VERSION ""

NS_ :

BS_:

BU_: DBW AKit Pacifica MPDM_Master MPDM_Requester

BO_ 3221225472 VECTOR__INDEPENDENT_SIG_MSG: 0 Vector__XXX
 SG_ DBW_SteeringWhlCurvDes m1 : 0|14@1- (0.0001,0) [-0.8192|0.8191] "1/m" Vector__XXX
 SG_ DBW_SteeringWhlCurvAct m1 : 0|14@1- (0.0001,0) [-0.8192|0.8191] "1/m" Vector__XXX
 SG_ DBW_SteeringUnitType M : 52|1@1+ (1,0) [0|1] "" Vector__XXX
 SG_ DBW_MiscFault_AccelRpt : 52|1@1+ (1,0) [0|1] "Bool" Vector__XXX
 SG_ DBW_MiscFault_BrkRpt : 49|1@1+ (1,0) [0|1] "Bool" Vector__XXX
 SG_ DBW_MiscFault_SteerRpt : 51|1@1+ (1,0) [0|1] "Bool" Vector__XXX
 SG_ AKit_SteeringWhlQuiet : 51|1@1+ (1,0) [0|1] "" Vector__XXX
 SG_ NewSignal_0004 : 0|8@1+ (1,0) [0|0] "" Vector__XXX
 SG_ NewSignal_0001 : 0|8@1+ (1,0) [0|0] "" Vector__XXX
 SG_ NewSignal_0008 : 32|8@1+ (1,0) [0|0] "" Vector__XXX
 SG_ NewSignal_0006 : 0|8@1+ (1,0) [0|0] "" Vector__XXX
 SG_ NewSignal_0002 : 0|8@1+ (1,0) [0|0] "" Vector__XXX
 SG_ NewSignal_0003 : 0|8@1+ (1,0) [0|0] "" Vector__XXX
 SG_ DBW_Mdpm2Fuse01 : 0|2@1+ (1,0) [0|3] "enum" Vector__XXX
 SG_ DBW_Mdpm2Fuse02 : 2|2@1+ (1,0) [0|3] "enum" Vector__XXX
 SG_ DBW_Mdpm2Fuse03 : 4|2@1+ (1,0) [0|3] "enum" Vector__XXX
 SG_ DBW_Mdpm2Fuse04 : 6|2@1+ (1,0) [0|3] "enum" Vector__XXX
 SG_ DBW_Mdpm2Fuse05 : 8|2@1+ (1,0) [0|3] "enum" Vector__XXX
 SG_ DBW_Mdpm2Fuse06 : 10|2@1+ (1,0) [0|3] "enum" Vector__XXX
 SG_ DBW_Mdpm2Fuse07 : 12|2@1+ (1,0) [0|3] "enum" Vector__XXX
 SG_ DBW_Mdpm2Fuse08 : 14|2@1+ (1,0) [0|3] "enum" Vector__XXX
 SG_ DBW_Mdpm2Fuse09 : 16|2@1+ (1,0) [0|3] "enum" Vector__XXX
 SG_ DBW_Mdpm2Fuse10 : 18|2@1+ (1,0) [0|3] "enum" Vector__XXX
 SG_ DBW_Mdpm2Fuse11 : 20|2@1+ (1,0) [0|3] "enum" Vector__XXX
 SG_ DBW_Mdpm2Fuse12 : 22|2@1+ (1,0) [0|3] "enum" Vector__XXX
 SG_ DBW_Mdpm2Fuse13 : 24|2@1+ (1,0) [0|3] "enum" Vector__XXX
 SG_ DBW_Mdpm2Fuse14 : 26|2@1+ (1,0) [0|3] "enum" Vector__XXX
 SG_ DBW_Mdpm2Fuse15 : 28|2@1+ (1,0) [0|3] "enum" Vector__XXX
 SG_ DBW_Mdpm2Fuse16 : 30|2@1+ (1,0) [0|3] "enum" Vector__XXX
 SG_ DBW_Mdpm2Relay01 : 32|4@1+ (1,0) [0|15] "enum" Vector__XXX
 SG_ DBW_Mdpm2Relay02 : 36|4@1+ (1,0) [0|15] "enum" Vector__XXX
 SG_ DBW_Mdpm2Relay03 : 40|4@1+ (1,0) [0|15] "enum" Vector__XXX
 SG_ DBW_Mdpm2Relay04 : 44|4@1+ (1,0) [0|15] "enum" Vector__XXX
 SG_ DBW_Mdpm2Relay05 : 48|4@1+ (1,0) [0|15] "enum" Vector__XXX
 SG_ DBW_Mdpm2Relay06 : 52|4@1+ (1,0) [0|15] "enum" Vector__XXX
 SG_ DBW_Mdpm2Relay07 : 56|4@1+ (1,0) [0|15] "enum" Vector__XXX
 SG_ DBW_Mdpm2Relay08 : 60|4@1+ (1,0) [0|15] "enum" Vector__XXX
 SG_ AKit_Mdpm1Relay01Cmd : 0|2@1+ (1,0) [0|3] "enum" Vector__XXX
 SG_ AKit_Mdpm1Relay02Cmd : 2|2@1+ (1,0) [0|3] "enum" Vector__XXX
 SG_ AKit_Mdpm1Relay03Cmd : 4|2@1+ (1,0) [0|3] "enum" Vector__XXX
 SG_ AKit_Mdpm1Relay04Cmd : 6|2@1+ (1,0) [0|3] "enum" Vector__XXX
 SG_ AKit_Mdpm1Relay05Cmd : 8|2@1+ (1,0) [0|3] "enum" Vector__XXX
 SG_ AKit_Mdpm1Relay06Cmd : 10|2@1+ (1,0) [0|3] "enum" Vector__XXX
 SG_ AKit_Mdpm1Relay07Cmd : 12|2@1+ (1,0) [0|3] "enum" Vector__XXX
 SG_ AKit_Mdpm1Relay08Cmd : 14|2@1+ (1,0) [0|3] "enum" Vector__XXX
 SG_ AKit_Mdpm2Relay01Cmd : 16|2@1+ (1,0) [0|3] "enum" Vector__XXX
 SG_ AKit_Mdpm2Relay02Cmd : 18|2@1+ (1,0) [0|3] "enum" Vector__XXX
 SG_ AKit_Mdpm2Relay03Cmd : 20|2@1+ (1,0) [0|3] "enum" Vector__XXX
 SG_ AKit_Mdpm2Relay04Cmd : 22|2@1+ (1,0) [0|3] "enum" Vector__XXX
 SG_ AKit_Mdpm2Relay05Cmd : 24|2@1+ (1,0) [0|3] "enum" Vector__XXX
 SG_ AKit_Mdpm2Relay06Cmd : 26|2@1+ (1,0) [0|3] "enum" Vector__XXX
 SG_ AKit_Mdpm2Relay07Cmd : 28|2@1+ (1,0) [0|3] "enum" Vector__XXX
 SG_ AKit_Mdpm2Relay08Cmd : 30|2@1+ (1,0) [0|3] "enum" Vector__XXX
 SG_ AKit_MdpmCmdWatchdogCntr : 56|4@1+ (1,0) [0|3] "" Vector__XXX
 SG_ DBW_Mdpm1Fuse01 : 0|2@1+ (1,0) [0|3] "enum" Vector__XXX
 SG_ DBW_Mdpm1Fuse02 : 2|2@1+ (1,0) [0|3] "enum" Vector__XXX
 SG_ DBW_Mdpm1Fuse03 : 4|2@1+ (1,0) [0|3] "enum" Vector__XXX
 SG_ DBW_Mdpm1Fuse04 : 6|2@1+ (1,0) [0|3] "enum" Vector__XXX
 SG_ DBW_Mdpm1Fuse05 : 8|2@1+ (1,0) [0|3] "enum" Vector__XXX
 SG_ DBW_Mdpm1Fuse06 : 10|2@1+ (1,0) [0|3] "enum" Vector__XXX
 SG_ DBW_Mdpm1Fuse07 : 12|2@1+ (1,0) [0|3] "enum" Vector__XXX
 SG_ DBW_Mdpm1Fuse08 : 14|2@1+ (1,0) [0|3] "enum" Vector__XXX
 SG_ DBW_Mdpm1Fuse09 : 16|2@1+ (1,0) [0|3] "enum" Vector__XXX
 SG_ DBW_Mdpm1Fuse10 : 18|2@1+ (1,0) [0|3] "enum" Vector__XXX
 SG_ DBW_Mdpm1Fuse11 : 20|2@1+ (1,0) [0|3] "enum" Vector__XXX
 SG_ DBW_Mdpm1Fuse12 : 22|2@1+ (1,0) [0|3] "enum" Vector__XXX
 SG_ DBW_Mdpm1Fuse13 : 24|2@1+ (1,0) [0|3] "enum" Vector__XXX
 SG_ DBW_Mdpm1Fuse14 : 26|2@1+ (1,0) [0|3] "enum" Vector__XXX
 SG_ DBW_Mdpm1Fuse15 : 28|2@1+ (1,0) [0|3] "enum" Vector__XXX
 SG_ DBW_Mdpm1Fuse16 : 30|2@1+ (1,0) [0|3] "enum" Vector__XXX
 SG_ DBW_Mdpm1Relay01 : 32|4@1+ (1,0) [0|15] "enum" Vector__XXX
 SG_ DBW_Mdpm1Relay02 : 36|4@1+ (1,0) [0|15] "enum" Vector__XXX
 SG_ DBW_Mdpm1Relay03 : 40|4@1+ (1,0) [0|15] "enum" Vector__XXX
 SG_ DBW_Mdpm1Relay04 : 44|4@1+ (1,0) [0|15] "enum" Vector__XXX
 SG_ DBW_Mdpm1Relay05 : 48|4@1+ (1,0) [0|15] "enum" Vector__XXX
 SG_ DBW_Mdpm1Relay06 : 52|4@1+ (1,0) [0|15] "enum" Vector__XXX
 SG_ DBW_Mdpm1Relay07 : 56|4@1+ (1,0) [0|15] "enum" Vector__XXX
 SG_ DBW_Mdpm1Relay08 : 60|4@1+ (1,0) [0|15] "enum" Vector__XXX
 SG_ DBW_GpsLong : 0|32@1+ (0.301749,0) [-648000000|648000000] "mas" Vector__XXX
 SG_ DBW_GpsLat : 32|32@1+ (0.301749,0) [-324000000|324000000] "mas" Vector__XXX
 SG_ VinMultiplexor M : 0|2@1+ (1,0) [0|2] "" Vector__XXX
 SG_ VinDigit_01 m0 : 8|8@1+ (1,0) [30|90] "ascii" Vector__XXX
 SG_ VinDigit_02 m0 : 16|8@1+ (1,0) [30|90] "ascii" Vector__XXX
 SG_ VinDigit_03 m0 : 24|8@1+ (1,0) [30|90] "ascii" Vector__XXX
 SG_ VinDigit_04 m0 : 32|8@1+ (1,0) [30|90] "ascii" Vector__XXX
 SG_ VinDigit_05 m0 : 40|8@1+ (1,0) [30|90] "ascii" Vector__XXX
 SG_ VinDigit_06 m0 : 48|8@1+ (1,0) [30|90] "ascii" Vector__XXX
 SG_ VinDigit_07 m0 : 56|8@1+ (1,0) [30|90] "ascii" Vector__XXX
 SG_ VinDigit_08 m1 : 8|8@1+ (1,0) [30|90] "ascii" Vector__XXX
 SG_ VinDigit_09 m1 : 16|8@1+ (1,0) [30|90] "ascii" Vector__XXX
 SG_ VinDigit_10 m1 : 24|8@1+ (1,0) [30|90] "ascii" Vector__XXX
 SG_ VinDigit_11 m1 : 32|8@1+ (1,0) [30|90] "ascii" Vector__XXX
 SG_ VinDigit_12 m1 : 40|8@1+ (1,0) [30|90] "ascii" Vector__XXX
 SG_ VinDigit_13 m1 : 48|8@1+ (1,0) [30|90] "ascii" Vector__XXX
 SG_ VinDigit_14 m1 : 56|8@1+ (1,0) [30|90] "ascii" Vector__XXX
 SG_ VinDigit_15 m2 : 8|8@1+ (1,0) [30|90] "ascii" Vector__XXX
 SG_ VinDigit_16 m2 : 16|8@1+ (1,0) [30|90] "ascii" Vector__XXX
 SG_ VinDigit_17 m2 : 24|8@1+ (1,0) [30|90] "ascii" Vector__XXX

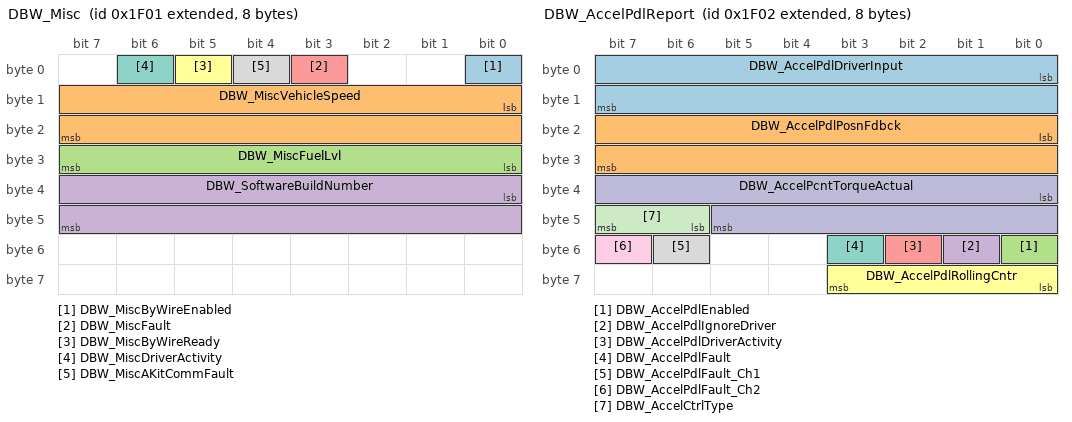
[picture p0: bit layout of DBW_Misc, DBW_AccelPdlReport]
BO_ 2147491585 DBW_Misc: 8 DBW
 SG_ DBW_MiscByWireEnabled : 0|1@1+ (1,0) [0|1] "Bool" Vector__XXX
 SG_ DBW_MiscVehicleSpeed : 8|16@1+ (0.00217014,0) [0|142.22] "m/s" Vector__XXX
 SG_ DBW_MiscFuelLvl : 24|8@1+ (0.5,0) [0|100] "%" Vector__XXX
 SG_ DBW_SoftwareBuildNumber : 32|16@1+ (1,0) [0|65535] "" Vector__XXX
 SG_ DBW_MiscFault : 3|1@1+ (1,0) [0|1] "Bool" Vector__XXX
 SG_ DBW_MiscByWireReady : 5|1@1+ (1,0) [0|1] "Bool" Vector__XXX
 SG_ DBW_MiscDriverActivity : 6|1@1+ (1,0) [0|1] "Bool" Vector__XXX
 SG_ DBW_MiscAKitCommFault : 4|1@1+ (1,0) [0|1] "Bool" Vector__XXX

BO_ 2147491586 DBW_AccelPdlReport: 8 DBW
 SG_ DBW_AccelPdlDriverInput : 0|16@1+ (0.1,0) [0|100] "%-pedal" Vector__XXX
 SG_ DBW_AccelPdlPosnFdbck : 16|16@1+ (0.1,0) [0|100] "%-pedal" Vector__XXX
 SG_ DBW_AccelPdlEnabled : 48|1@1+ (1,0) [0|1] "Bool" Vector__XXX
 SG_ DBW_AccelPdlIgnoreDriver : 49|1@1+ (1,0) [0|1] "Bool" Vector__XXX
 SG_ DBW_AccelPdlDriverActivity : 50|1@1+ (1,0) [0|1] "Bool" Vector__XXX
 SG_ DBW_AccelPdlRollingCntr : 56|4@1+ (1,0) [0|15] "" Vector__XXX
 SG_ DBW_AccelPdlFault : 51|1@1+ (1,0) [0|1] "Bool" Vector__XXX
 SG_ DBW_AccelPdlFault_Ch1 : 54|1@1+ (1,0) [0|1] "Bool" Vector__XXX
 SG_ DBW_AccelPdlFault_Ch2 : 55|1@1+ (1,0) [0|1] "Bool" Vector__XXX
 SG_ DBW_AccelPcntTorqueActual : 32|14@1+ (0.1,0) [0|100] "%-pedal" Vector__XXX
 SG_ DBW_AccelCtrlType : 46|2@1+ (1,0) [0|3] "Enum" Vector__XXX

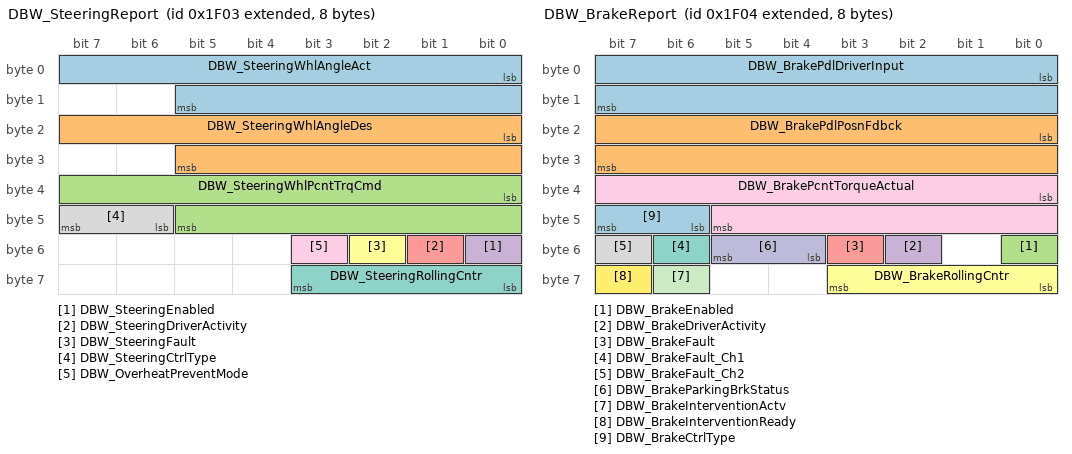
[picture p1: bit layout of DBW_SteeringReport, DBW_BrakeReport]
BO_ 2147491587 DBW_SteeringReport: 8 DBW
 SG_ DBW_SteeringWhlAngleAct : 0|14@1- (0.1,0) [-600|600] "deg" Vector__XXX
 SG_ DBW_SteeringWhlAngleDes : 16|14@1- (0.1,0) [-600|600] "deg" Vector__XXX
 SG_ DBW_SteeringWhlPcntTrqCmd : 32|14@1- (0.02,0) [-100|100] "%-torque" Vector__XXX
 SG_ DBW_SteeringEnabled : 48|1@1+ (1,0) [0|1] "Bool" Vector__XXX
 SG_ DBW_SteeringDriverActivity : 49|1@1+ (1,0) [0|1] "Bool" Vector__XXX
 SG_ DBW_SteeringFault : 50|1@1+ (1,0) [0|1] "Bool" Vector__XXX
 SG_ DBW_SteeringRollingCntr : 56|4@1+ (1,0) [0|15] "" Vector__XXX
 SG_ DBW_SteeringCtrlType : 46|2@1+ (1,0) [0|3] "Enum" Vector__XXX
 SG_ DBW_OverheatPreventMode : 51|1@1+ (1,0) [0|1] "Bool" Vector__XXX

BO_ 2147491588 DBW_BrakeReport: 8 DBW
 SG_ DBW_BrakePdlDriverInput : 0|16@1+ (0.1,0) [0|100] "%-pedal" Vector__XXX
 SG_ DBW_BrakePdlPosnFdbck : 16|16@1+ (0.1,0) [0|100] "%-pedal" Vector__XXX
 SG_ DBW_BrakeEnabled : 48|1@1+ (1,0) [0|1] "Bool" Vector__XXX
 SG_ DBW_BrakeDriverActivity : 50|1@1+ (1,0) [0|1] "Bool" Vector__XXX
 SG_ DBW_BrakeFault : 51|1@1+ (1,0) [0|1] "Bool" Vector__XXX
 SG_ DBW_BrakeRollingCntr : 56|4@1+ (1,0) [0|15] "" Vector__XXX
 SG_ DBW_BrakeFault_Ch1 : 54|1@1+ (1,0) [0|1] "Bool" Vector__XXX
 SG_ DBW_BrakeFault_Ch2 : 55|1@1+ (1,0) [0|1] "Bool" Vector__XXX
 SG_ DBW_BrakePcntTorqueActual : 32|14@1+ (0.1,0) [0|100] "%-torque" Vector__XXX
 SG_ DBW_BrakeParkingBrkStatus : 52|2@1+ (1,0) [0|3] "Enum" Vector__XXX
 SG_ DBW_BrakeInterventionActv : 62|1@1+ (1,0) [0|1] "Bool" Vector__XXX
 SG_ DBW_BrakeInterventionReady : 63|1@1+ (1,0) [0|1] "Bool" Vector__XXX
 SG_ DBW_BrakeCtrlType : 46|2@1+ (1,0) [0|3] "Enum" Vector__XXX

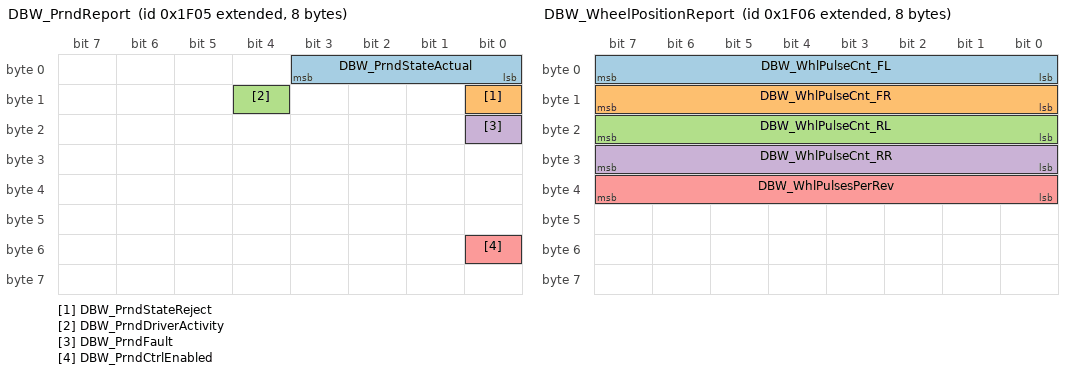
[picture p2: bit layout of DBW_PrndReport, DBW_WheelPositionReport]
BO_ 2147491589 DBW_PrndReport: 8 DBW
 SG_ DBW_PrndStateActual : 0|4@1+ (1,0) [0|4] "Enum" Vector__XXX
 SG_ DBW_PrndStateReject : 8|1@1+ (1,0) [0|1] "Bool" Vector__XXX
 SG_ DBW_PrndDriverActivity : 12|1@1+ (1,0) [0|1] "Bool" Vector__XXX
 SG_ DBW_PrndFault : 16|1@1+ (1,0) [0|1] "Bool" Vector__XXX
 SG_ DBW_PrndCtrlEnabled : 48|1@1+ (1,0) [0|1] "Bool" Vector__XXX

BO_ 2147491590 DBW_WheelPositionReport: 8 DBW
 SG_ DBW_WhlPulseCnt_FL : 0|8@1+ (1,0) [0|254] "Count" Vector__XXX
 SG_ DBW_WhlPulseCnt_FR : 8|8@1+ (1,0) [0|254] "Count" Vector__XXX
 SG_ DBW_WhlPulseCnt_RL : 16|8@1+ (1,0) [0|254] "Count" Vector__XXX
 SG_ DBW_WhlPulseCnt_RR : 24|8@1+ (1,0) [0|254] "Count" Vector__XXX
 SG_ DBW_WhlPulsesPerRev : 32|8@1+ (1,0) [0|255] "Count" Vector__XXX

BO_ 2147495682 AKit_AccelPdlRequest: 8 AKit
 SG_ AKit_AccelPdlReq m0 : 0|14@1+ (0.1,0) [0|100] "%-pedal" Vector__XXX
 SG_ AKit_AccelPdlEnblReq : 48|1@1+ (1,0) [0|1] "Bool" Vector__XXX
 SG_ Akit_AccelPdlIgnoreDriverOvrd : 50|1@1+ (1,0) [0|1] "Bool" Vector__XXX
 SG_ AKit_AccelPdlRollingCntr : 56|4@1+ (1,0) [0|15] "" Vector__XXX
 SG_ AKit_AccelReqType M : 54|2@1+ (1,0) [0|3] "Enum" Vector__XXX
 SG_ AKit_AccelPcntTorqueReq m1 : 0|14@1+ (0.1,0) [0|100] "%-torque" Vector__XXX
 SG_ AKit_SpeedReq m2 : 0|14@1+ (0.005,0) [0|81.915] "m/s" Vector__XXX
 SG_ AKit_SpeedModeRoadSlope m2 : 32|8@1- (0.2,0) [-25.5|25.5] "degrees" Vector__XXX

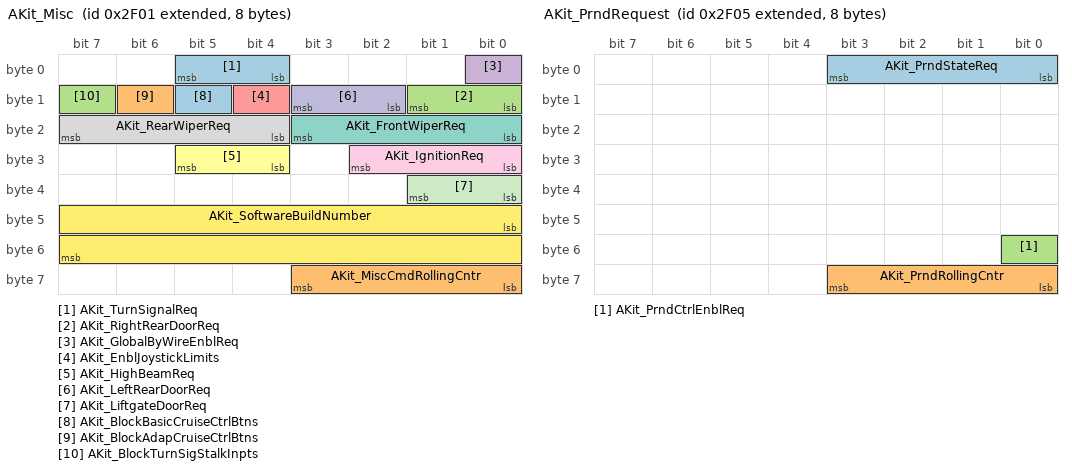
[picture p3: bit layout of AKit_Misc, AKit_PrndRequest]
BO_ 2147495681 AKit_Misc: 8 AKit
 SG_ AKit_TurnSignalReq : 4|2@1+ (1,0) [0|3] "Enum" Vector__XXX
 SG_ AKit_MiscCmdRollingCntr : 56|4@1+ (1,0) [0|15] "" Vector__XXX
 SG_ AKit_RightRearDoorReq : 8|2@1+ (1,0) [0|3] "Enum" Vector__XXX
 SG_ AKit_GlobalByWireEnblReq : 0|1@1+ (1,0) [0|1] "Bool" Vector__XXX
 SG_ AKit_EnblJoystickLimits : 12|1@1+ (1,0) [0|1] "Bool" Vector__XXX
 SG_ AKit_HighBeamReq : 28|2@1+ (1,0) [0|0] "" Vector__XXX
 SG_ AKit_FrontWiperReq : 16|4@1+ (1,0) [0|15] "Enum" Vector__XXX
 SG_ AKit_RearWiperReq : 20|4@1+ (1,0) [0|15] "Enum" Vector__XXX
 SG_ AKit_IgnitionReq : 24|3@1+ (1,0) [0|7] "Enum" Vector__XXX
 SG_ AKit_LeftRearDoorReq : 10|2@1+ (1,0) [0|3] "Enum" Vector__XXX
 SG_ AKit_LiftgateDoorReq : 32|2@1+ (1,0) [0|3] "Enum" Vector__XXX
 SG_ AKit_SoftwareBuildNumber : 40|16@1+ (1,0) [0|65535] "" Vector__XXX
 SG_ AKit_BlockBasicCruiseCtrlBtns : 13|1@1+ (1,0) [0|1] "" Vector__XXX
 SG_ AKit_BlockAdapCruiseCtrlBtns : 14|1@1+ (1,0) [0|1] "" Vector__XXX
 SG_ AKit_BlockTurnSigStalkInpts : 15|1@1+ (1,0) [0|1] "" Vector__XXX

BO_ 2147495683 AKit_SteeringRequest: 8 AKit
 SG_ AKit_SteeringWhlAngleReq m1 : 0|14@1- (0.1,0) [-500|500] "deg" Vector__XXX
 SG_ AKit_SteeringWhlAngleVelocityLim : 16|16@1- (1,0) [0|498] "deg/s" Vector__XXX
 SG_ AKit_SteerCtrlEnblReq : 48|1@1+ (1,0) [0|0] "" Vector__XXX
 SG_ AKit_SteerRollingCntr : 56|4@1+ (1,0) [0|15] "" Vector__XXX
 SG_ AKit_SteeringWhlIgnoreDriverOvrd : 50|1@1+ (1,0) [0|1] "" Vector__XXX
 SG_ AKit_SteeringWhlPcntTrqReq m0 : 0|14@1- (0.02,0) [-100|100] "%-torque" Vector__XXX
 SG_ AKit_SteeringReqType M : 54|2@1+ (1,0) [0|3] "Enum" Vector__XXX
 SG_ AKit_SteeringVehCurvatureReq m2 : 0|14@1- (0.0001,0) [-0.8192|0.8191] "1/m" Vector__XXX

BO_ 2147495684 AKit_BrakeRequest: 8 AKit
 SG_ AKit_BrakePedalReq m0 : 0|14@1+ (0.1,0) [0|100] "%-pedal" Vector__XXX
 SG_ AKit_BrakeRollingCntr : 56|4@1+ (1,0) [0|15] "" Vector__XXX
 SG_ AKit_BrakeCtrlEnblReq : 48|1@1+ (1,0) [0|1] "Bool" Vector__XXX
 SG_ AKit_BrakeCtrlReqType M : 54|2@1+ (1,0) [0|3] "Enum" Vector__XXX
 SG_ AKit_BrakePcntTorqueReq m1 : 0|14@1+ (0.1,0) [0|100] "%-torque" Vector__XXX
 SG_ AKit_SpeedModeAccelLim m2 : 16|8@1+ (0.1,0) [0|25.5] "m/s^2" Vector__XXX
 SG_ AKit_SpeedModeDecelLim m2 : 24|8@1+ (0.1,0) [0|25.5] "m/s^2" Vector__XXX

BO_ 2147495685 AKit_PrndRequest: 8 AKit
 SG_ AKit_PrndStateReq : 0|4@1+ (1,0) [0|5] "Enum" Vector__XXX
 SG_ AKit_PrndRollingCntr : 56|4@1+ (1,0) [0|15] "" Vector__XXX
 SG_ AKit_PrndCtrlEnblReq : 48|1@1+ (1,0) [0|1] "Bool" Vector__XXX

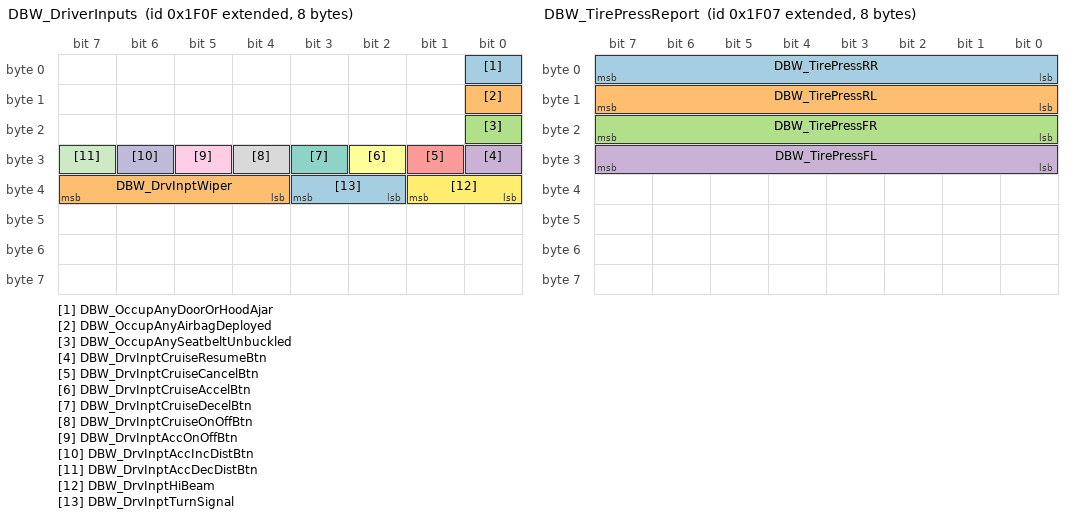
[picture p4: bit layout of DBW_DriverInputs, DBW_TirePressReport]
BO_ 2147491599 DBW_DriverInputs: 8 AKit
 SG_ DBW_OccupAnyDoorOrHoodAjar : 0|1@1+ (1,0) [0|1] "Bool" Vector__XXX
 SG_ DBW_OccupAnyAirbagDeployed : 8|1@1+ (1,0) [0|1] "Bool" Vector__XXX
 SG_ DBW_OccupAnySeatbeltUnbuckled : 16|1@1+ (1,0) [0|1] "Bool" Vector__XXX
 SG_ DBW_DrvInptCruiseResumeBtn : 24|1@1+ (1,0) [0|1] "Bool" Vector__XXX
 SG_ DBW_DrvInptCruiseCancelBtn : 25|1@1+ (1,0) [0|1] "Bool" Vector__XXX
 SG_ DBW_DrvInptCruiseAccelBtn : 26|1@1+ (1,0) [0|1] "Bool" Vector__XXX
 SG_ DBW_DrvInptCruiseDecelBtn : 27|1@1+ (1,0) [0|1] "Bool" Vector__XXX
 SG_ DBW_DrvInptCruiseOnOffBtn : 28|1@1+ (1,0) [0|1] "Bool" Vector__XXX
 SG_ DBW_DrvInptAccOnOffBtn : 29|1@1+ (1,0) [0|1] "Bool" Vector__XXX
 SG_ DBW_DrvInptAccIncDistBtn : 30|1@1+ (1,0) [0|1] "Bool" Vector__XXX
 SG_ DBW_DrvInptAccDecDistBtn : 31|1@1+ (1,0) [0|1] "Bool" Vector__XXX
 SG_ DBW_DrvInptHiBeam : 32|2@1+ (1,0) [0|3] "enum" Vector__XXX
 SG_ DBW_DrvInptTurnSignal : 34|2@1+ (1,0) [0|3] "enum" Vector__XXX
 SG_ DBW_DrvInptWiper : 36|4@1+ (1,0) [0|15] "enum" Vector__XXX

BO_ 2147491591 DBW_TirePressReport: 8 DBW
 SG_ DBW_TirePressRR : 0|8@1+ (6.89476,0) [0|868.739] "kPa" Vector__XXX
 SG_ DBW_TirePressRL : 8|8@1+ (6.89476,0) [0|868.739] "kPa" Vector__XXX
 SG_ DBW_TirePressFR : 16|8@1+ (6.89476,0) [0|868.739] "kPa" Vector__XXX
 SG_ DBW_TirePressFL : 24|8@1+ (6.89476,0) [0|868.739] "kPa" Vector__XXX

BO_ 2147491592 DBW_VinReport: 8 DBW
 SG_ DBW_VinMultiplexor M : 0|2@1+ (1,0) [0|2] "" Vector__XXX
 SG_ DBW_VinDigit_01 m0 : 8|8@1+ (1,0) [30|90] "ascii" Vector__XXX
 SG_ DBW_VinDigit_02 m0 : 16|8@1+ (1,0) [30|90] "ascii" Vector__XXX
 SG_ DBW_VinDigit_03 m0 : 24|8@1+ (1,0) [30|90] "ascii" Vector__XXX
 SG_ DBW_VinDigit_04 m0 : 32|8@1+ (1,0) [30|90] "ascii" Vector__XXX
 SG_ DBW_VinDigit_05 m0 : 40|8@1+ (1,0) [30|90] "ascii" Vector__XXX
 SG_ DBW_VinDigit_06 m0 : 48|8@1+ (1,0) [30|90] "ascii" Vector__XXX
 SG_ DBW_VinDigit_07 m0 : 56|8@1+ (1,0) [30|90] "ascii" Vector__XXX
 SG_ DBW_VinDigit_08 m1 : 8|8@1+ (1,0) [30|90] "ascii" Vector__XXX
 SG_ DBW_VinDigit_09 m1 : 16|8@1+ (1,0) [30|90] "ascii" Vector__XXX
 SG_ DBW_VinDigit_10 m1 : 24|8@1+ (1,0) [30|90] "ascii" Vector__XXX
 SG_ DBW_VinDigit_11 m1 : 32|8@1+ (1,0) [30|90] "ascii" Vector__XXX
 SG_ DBW_VinDigit_12 m1 : 40|8@1+ (1,0) [30|90] "ascii" Vector__XXX
 SG_ DBW_VinDigit_13 m1 : 48|8@1+ (1,0) [30|90] "ascii" Vector__XXX
 SG_ DBW_VinDigit_14 m1 : 56|8@1+ (1,0) [30|90] "ascii" Vector__XXX
 SG_ DBW_VinDigit_15 m2 : 8|8@1+ (1,0) [30|90] "ascii" Vector__XXX
 SG_ DBW_VinDigit_16 m2 : 16|8@1+ (1,0) [30|90] "ascii" Vector__XXX
 SG_ DBW_VinDigit_17 m2 : 24|8@1+ (1,0) [30|90] "ascii" Vector__XXX

BO_ 2147491593 DBW_Reserved1: 8 DBW

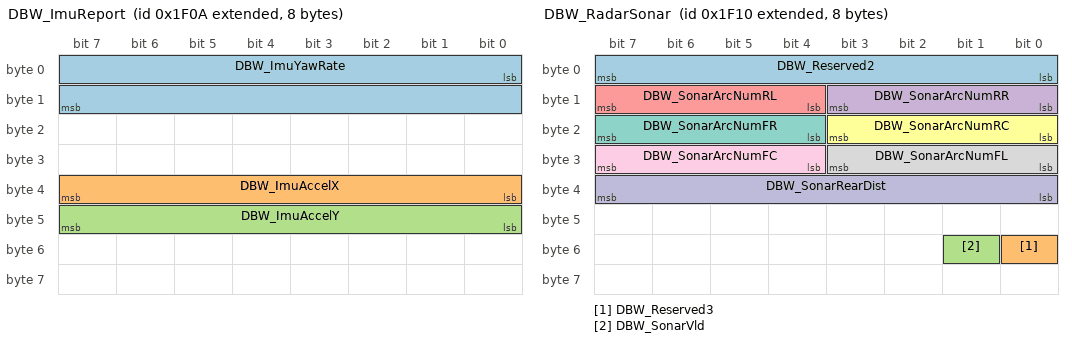
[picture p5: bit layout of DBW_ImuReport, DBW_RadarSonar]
BO_ 2147491594 DBW_ImuReport: 8 DBW
 SG_ DBW_ImuYawRate : 0|16@1+ (0.01,-327.68) [-327.68|327.66] "deg/sec" Vector__XXX
 SG_ DBW_ImuAccelX : 32|8@1+ (0.08,-10.24) [-10.24|10.08] "m/s/s" Vector__XXX
 SG_ DBW_ImuAccelY : 40|8@1+ (0.08,-10.24) [-10.24|10.08] "m/s/s" Vector__XXX

BO_ 2147491595 DBW_WheelSpeedReport: 8 DBW
 SG_ DBW_WhlRpm_RR m0 : 53|14@0- (0.5,-8192) [-8192|8191] "rpm" Vector__XXX
 SG_ DBW_WhlRpm_RL m0 : 37|14@0- (0.5,-8192) [-8192|8191] "rpm" Vector__XXX
 SG_ DBW_WhlRpm_FR m0 : 21|14@0- (0.5,-8192) [-8192|8191] "rpm" Vector__XXX
 SG_ DBW_WhlRpm_FL m0 : 5|14@0- (0.5,-8192) [-8192|8191] "rpm" Vector__XXX
 SG_ DBW_WhlSpdType M : 6|2@1+ (1,0) [0|3] "" Vector__XXX
 SG_ DBW_WhlSpd_RR m2 : 40|17@0- (0.00390625,0) [-250.996|250.996] "km/h" Vector__XXX
 SG_ DBW_WhlSpd_RL m2 : 16|17@0- (0.00390625,0) [-250.996|250.996] "km/h" Vector__XXX
 SG_ DBW_WhlSpd_FR m1 : 40|17@0- (0.00390625,0) [-250.996|250.996] "km/h" Vector__XXX
 SG_ DBW_WhlSpd_FL m1 : 16|17@0- (0.00390625,0) [-250.996|250.996] "km/h" Vector__XXX

BO_ 2147491600 DBW_RadarSonar: 8 DBW
 SG_ DBW_Reserved2 : 0|8@1+ (1,0) [0|253] "m" Vector__XXX
 SG_ DBW_Reserved3 : 48|1@1+ (1,0) [0|1] "Bool" Vector__XXX
 SG_ DBW_SonarVld : 49|1@1+ (1,0) [0|1] "Bool" Vector__XXX
 SG_ DBW_SonarArcNumRR : 8|4@1+ (1,0) [0|0] "Enum" Vector__XXX
 SG_ DBW_SonarArcNumRL : 12|4@1+ (1,0) [0|0] "Enum" Vector__XXX
 SG_ DBW_SonarArcNumRC : 16|4@1+ (1,0) [0|0] "Enum" Vector__XXX
 SG_ DBW_SonarArcNumFR : 20|4@1+ (1,0) [0|0] "Enum" Vector__XXX
 SG_ DBW_SonarArcNumFL : 24|4@1+ (1,0) [0|0] "Enum" Vector__XXX
 SG_ DBW_SonarArcNumFC : 28|4@1+ (1,0) [0|0] "Enum" Vector__XXX
 SG_ DBW_SonarRearDist : 32|8@1+ (0.01,0) [0|2.54] "m" Vector__XXX

BO_ 1807 DBW_FaultText: 8 DBW
 SG_ FltTxt_PageNum M : 0|8@1+ (1,0) [0|255] "" Vector__XXX
 SG_ FltTxt_FaultId m0 : 15|16@0+ (1,0) [0|65535] "" Vector__XXX
 SG_ FltTxt_NumPages m0 : 40|8@1+ (1,0) [0|10] "" Vector__XXX
 SG_ FltTxt_FaultStatus m0 : 48|8@1+ (1,0) [0|2] "enum" Vector__XXX
 SG_ FltTxt_FaultSetRuntime m255 : 15|32@0+ (1,0) [0|0] "ms" Vector__XXX
 SG_ FltTxt_CRC m255 : 56|8@1+ (1,0) [0|255] "" Vector__XXX
 SG_ FltTxt_CurrentRuntime m254 : 39|32@0+ (1,0) [0|0] "ms" Vector__XXX
 SG_ FltTxt_Char01 m1 : 8|8@1+ (1,0) [0|255] "ascii" Vector__XXX
 SG_ FltTxt_Char02 m1 : 16|8@1+ (1,0) [0|255] "ascii" Vector__XXX
 SG_ FltTxt_Char03 m1 : 24|8@1+ (1,0) [0|255] "ascii" Vector__XXX
 SG_ FltTxt_Char04 m1 : 32|8@1+ (1,0) [0|255] "ascii" Vector__XXX
 SG_ FltTxt_Char05 m1 : 40|8@1+ (1,0) [0|255] "ascii" Vector__XXX
 SG_ FltTxt_Char06 m1 : 48|8@1+ (1,0) [0|255] "ascii" Vector__XXX
 SG_ FltTxt_Char07 m1 : 56|8@1+ (1,0) [0|255] "ascii" Vector__XXX
 SG_ FltTxt_Char08 m2 : 8|8@1+ (1,0) [0|255] "ascii" Vector__XXX
 SG_ FltTxt_Char09 m2 : 16|8@1+ (1,0) [0|255] "ascii" Vector__XXX
 SG_ FltTxt_Char10 m2 : 24|8@1+ (1,0) [0|255] "ascii" Vector__XXX
 SG_ FltTxt_Char11 m2 : 32|8@1+ (1,0) [0|255] "ascii" Vector__XXX
 SG_ FltTxt_Char12 m2 : 40|8@1+ (1,0) [0|255] "ascii" Vector__XXX
 SG_ FltTxt_Char13 m2 : 48|8@1+ (1,0) [0|255] "ascii" Vector__XXX
 SG_ FltTxt_Char14 m2 : 56|8@1+ (1,0) [0|255] "ascii" Vector__XXX
 SG_ FltTxt_Char15 m3 : 8|8@1+ (1,0) [0|255] "ascii" Vector__XXX
 SG_ FltTxt_Char16 m3 : 16|8@1+ (1,0) [0|255] "ascii" Vector__XXX
 SG_ FltTxt_Char17 m3 : 24|8@1+ (1,0) [0|255] "ascii" Vector__XXX
 SG_ FltTxt_Char18 m3 : 32|8@1+ (1,0) [0|255] "ascii" Vector__XXX
 SG_ FltTxt_Char19 m3 : 40|8@1+ (1,0) [0|255] "ascii" Vector__XXX
 SG_ FltTxt_Char20 m3 : 48|8@1+ (1,0) [0|255] "ascii" Vector__XXX
 SG_ FltTxt_Char21 m3 : 56|8@1+ (1,0) [0|255] "ascii" Vector__XXX
 SG_ FltTxt_Char22 m4 : 8|8@1+ (1,0) [0|255] "ascii" Vector__XXX
 SG_ FltTxt_Char23 m4 : 16|8@1+ (1,0) [0|255] "ascii" Vector__XXX
 SG_ FltTxt_Char24 m4 : 24|8@1+ (1,0) [0|255] "ascii" Vector__XXX
 SG_ FltTxt_Char25 m4 : 32|8@1+ (1,0) [0|255] "ascii" Vector__XXX
 SG_ FltTxt_Char26 m4 : 40|8@1+ (1,0) [0|255] "ascii" Vector__XXX
 SG_ FltTxt_Char27 m4 : 48|8@1+ (1,0) [0|255] "ascii" Vector__XXX
 SG_ FltTxt_Char28 m4 : 56|8@1+ (1,0) [0|255] "ascii" Vector__XXX
 SG_ FltTxt_Char29 m5 : 8|8@1+ (1,0) [0|255] "ascii" Vector__XXX
 SG_ FltTxt_Char30 m5 : 16|8@1+ (1,0) [0|255] "ascii" Vector__XXX
 SG_ FltTxt_Char31 m5 : 24|8@1+ (1,0) [0|255] "ascii" Vector__XXX
 SG_ FltTxt_Char32 m5 : 32|8@1+ (1,0) [0|255] "ascii" Vector__XXX
 SG_ FltTxt_Char33 m5 : 40|8@1+ (1,0) [0|255] "ascii" Vector__XXX
 SG_ FltTxt_Char34 m5 : 48|8@1+ (1,0) [0|255] "ascii" Vector__XXX
 SG_ FltTxt_Char35 m5 : 56|8@1+ (1,0) [0|255] "ascii" Vector__XXX
 SG_ FltTxt_Char36 m6 : 8|8@1+ (1,0) [0|255] "ascii" Vector__XXX
 SG_ FltTxt_Char37 m6 : 16|8@1+ (1,0) [0|255] "ascii" Vector__XXX
 SG_ FltTxt_Char38 m6 : 24|8@1+ (1,0) [0|255] "ascii" Vector__XXX
 SG_ FltTxt_Char39 m6 : 32|8@1+ (1,0) [0|255] "ascii" Vector__XXX
 SG_ FltTxt_Char40 m6 : 40|8@1+ (1,0) [0|255] "ascii" Vector__XXX
 SG_ FltTxt_Char41 m6 : 48|8@1+ (1,0) [0|255] "ascii" Vector__XXX
 SG_ FltTxt_Char42 m6 : 56|8@1+ (1,0) [0|255] "ascii" Vector__XXX
 SG_ FltTxt_Char43 m7 : 8|8@1+ (1,0) [0|255] "ascii" Vector__XXX
 SG_ FltTxt_Char44 m7 : 16|8@1+ (1,0) [0|255] "ascii" Vector__XXX
 SG_ FltTxt_Char45 m7 : 24|8@1+ (1,0) [0|255] "ascii" Vector__XXX
 SG_ FltTxt_Char46 m7 : 32|8@1+ (1,0) [0|255] "ascii" Vector__XXX
 SG_ FltTxt_Char47 m7 : 40|8@1+ (1,0) [0|255] "ascii" Vector__XXX
 SG_ FltTxt_Char48 m7 : 48|8@1+ (1,0) [0|255] "ascii" Vector__XXX
 SG_ FltTxt_Char49 m7 : 56|8@1+ (1,0) [0|255] "ascii" Vector__XXX

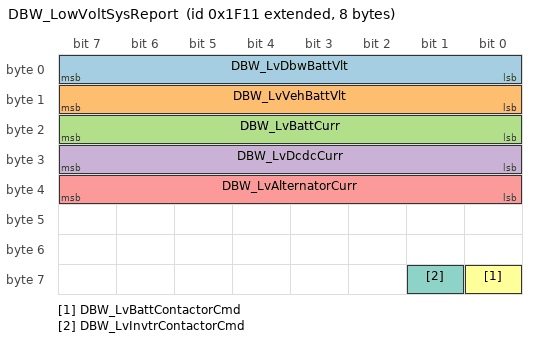
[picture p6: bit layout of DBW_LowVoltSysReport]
BO_ 2147491601 DBW_LowVoltSysReport: 8 DBW
 SG_ DBW_LvDbwBattVlt : 0|8@1+ (0.1,0) [0|25.5] "V" Vector__XXX
 SG_ DBW_LvVehBattVlt : 8|8@1+ (0.1,0) [0|25.5] "V" Vector__XXX
 SG_ DBW_LvBattCurr : 16|8@1+ (1,0) [0|255] "A" Vector__XXX
 SG_ DBW_LvDcdcCurr : 24|8@1+ (1,0) [0|255] "A" Vector__XXX
 SG_ DBW_LvAlternatorCurr : 32|8@1+ (1,0) [0|255] "A" Vector__XXX
 SG_ DBW_LvBattContactorCmd : 56|1@1+ (1,0) [0|1] "Bool" Vector__XXX
 SG_ DBW_LvInvtrContactorCmd : 57|1@1+ (1,0) [0|1] "Bool" Vector__XXX

BO_ 2147491602 DBW_BrakeReport2: 8 DBW
 SG_ DBW_BrakePress_bar : 0|14@1+ (0.02,0) [0|200] "bar_gauge" Vector__XXX
 SG_ DBW_RoadSlopeEstimate : 16|8@1- (0.2,0) [-25.5|25.5] "degress" Vector__XXX

BO_ 2147491603 DBW_SteeringReport2: 8 DBW
 SG_ DBW_SteeringVehCurvatureAct : 0|14@1- (0.0001,0) [-0.8192|0.8192] "1/m" Vector__XXX

CM_ BU_ Pacifica "Just added a custom VIN-read message from this module";
CM_ BU_ MPDM_Master "Whichever module directly controls MPDM would be the MPDM Master (broadcasts status to other modules)";
CM_ BU_ MPDM_Requester "Any module that doesn't directly control the MPDM but might want to request a state would be an MPDM_Requester";
CM_ SG_ 3221225472 DBW_SteeringWhlCurvDes "Position that the DBW is trying to acheive.";
CM_ SG_ 3221225472 DBW_SteeringWhlCurvAct "Actual position of the steering wheel";
CM_ SG_ 3221225472 DBW_SteeringUnitType "Multiplexor used to switch between reports of steering angle and steering curvature, depending on how the AKit is controlling the system. The DBW will switch feedback types based on what unit request is coming in from the AKit.";
CM_ SG_ 3221225472 DBW_MiscFault_AccelRpt "Same signal as DBW_MiscFault in the DBW_Misc message. Just duplicated here so it's easier to read on-screen in the ROS data viewing utility.";
CM_ SG_ 3221225472 DBW_MiscFault_BrkRpt "Same signal as DBW_MiscFault in the DBW_Misc message. Just duplicated here so it's easier to read on-screen in the ROS data viewing utility.";
CM_ SG_ 3221225472 DBW_MiscFault_SteerRpt "Same signal as DBW_MiscFault in the DBW_Misc message. Just duplicated here so it's easier to read on-screen in the ROS data viewing utility.";
CM_ SG_ 3221225472 AKit_SteeringWhlQuiet "What does \"quiet\" mean???";
CM_ SG_ 3221225472 AKit_MdpmCmdWatchdogCntr "Watchdog alive rolling counter";
CM_ SG_ 3221225472 DBW_GpsLong "need to determing what \"mas\" scaling is. negative means west.";
CM_ SG_ 3221225472 DBW_GpsLat "need to determing what \"mas\" scaling is. negative means south.";
CM_ BO_ 2147491585 "Must be sent continuously.";
CM_ SG_ 2147491585 DBW_MiscByWireEnabled "Actual mode of the Drive-By-Wire system. THis is NOT read by the ROS system, it's only here so its in CAN logs for debugging purposes";
CM_ SG_ 2147491585 DBW_MiscVehicleSpeed "scaled to match Pacifica's vehicle speed message";
CM_ SG_ 2147491585 DBW_MiscFuelLvl "DBW will have to read IC_A1:AvgFuelLvl (liters) from the Pacifica and divide it by VehCfg3:VC_FUEL_CAP";
CM_ SG_ 2147491585 DBW_SoftwareBuildNumber "Build number of the software that is currently flashed on the DBW control module";
CM_ SG_ 2147491585 DBW_MiscFault "indicates one of the DBW actuators has faulted out. See individual report messages for more details.";
CM_ SG_ 2147491585 DBW_MiscByWireReady "Indicates the DBW is ready (vehicle running and not faulted) to enable if the AKit chooses to send an enable request. Driver overrides are not an input to this flag, so in some cases this flag will be true but by-wire control still might not be enabled.";
CM_ SG_ 2147491585 DBW_MiscDriverActivity "Indicates the DBW has detected a driver overriding one of the actuators. This will disable by-wire operation until the enable request for the offending actuator is reset to zero. Note: Driver overrides will not clear the \"DBW_MiscByWireReady\" flag.";
CM_ SG_ 2147491585 DBW_MiscAKitCommFault "Sets in conjunction with DBW_MiscFault IFF the DBW fault is related to losing communication with the autonomous system. This may have different fault actions than other faults in the DBW system.
Note: when this sets, the most often reason is because the AKit is not sending all 5 of the AKit* command messages. All 5 must be send, even if some of the enable requests are false.";
CM_ BO_ 2147491586 "Must be sent continuously, even if you're not planning to enable this actuator.";
CM_ SG_ 2147491586 DBW_AccelPdlPosnFdbck "Feedback from the Vehicle's Engine or Hybrid Control Module. 
For J1939 vehicles with TSC1 control (Volvo), this is a %-of-reference-torque.
For all other vehicles with physical pedal wiring intercepts (Pacifica), this is a %-of-pedal-position";
CM_ SG_ 2147491586 DBW_AccelPdlIgnoreDriver "indicates the DBW system was requested by the AKit to ignore the driver's input.";
CM_ SG_ 2147491586 DBW_AccelPdlDriverActivity "Driver is pressing the accel pedal, which will switch the DBW system to manual mode unless the AKit is sending the AccelPdlIgnoreDriver flag. This flag latches and will unlatch when AKit_AccelPdlCtrlEnblCmd goes back to false.";
CM_ SG_ 2147491586 DBW_AccelPdlRollingCntr "Watchdog alive rolling counter";
CM_ SG_ 2147491586 DBW_AccelPdlFault "AccelPdl system has a fault, either from the vehicle itself or from an error in the request message from the AKit";
CM_ SG_ 2147491586 DBW_AccelPdlFault_Ch1 "VCU has detected hardware fault on accel pedal sig 1";
CM_ SG_ 2147491586 DBW_AccelPdlFault_Ch2 "VCU has detected hardware fault on accel pedal sig 2";
CM_ SG_ 2147491586 DBW_AccelPcntTorqueActual "This value is in % of a fixed reference value. This reference value depends only on the type of vehicle. Contact New Eagle to determine the reference value for your vehicle make/model.";
CM_ SG_ 2147491586 DBW_AccelCtrlType "Indicates whether the DBW kit is set to apply an open loop command (AKit responsible for performing all PID control),
 or requesting the DBW to apply PID control at the actuator level (turn wheel to a certain angle, or apply a certain amount of accel/brake torque & let AKit perform PID control on vehicle curvature/speed)
or requesting the DBW to perform all PID control at the vehicle level (control to a vehicle curvature and speed). If ReqType is 2, the requested speed will be taken from the signal AKit_SpeedReq in the AKit_AccelRequest message.
Some vehicles may not support all types!";
CM_ BO_ 2147491587 "Must be sent continuously, even if you're not planning to enable this actuator.";
CM_ SG_ 2147491587 DBW_SteeringWhlAngleAct "Actual position of the steering wheel. counterclockwise = positive";
CM_ SG_ 2147491587 DBW_SteeringWhlAngleDes "Position that the DBW is trying to acheive. counterclockwise = positive";
CM_ SG_ 2147491587 DBW_SteeringWhlPcntTrqCmd "Torque requested by the DBW to acheive the desired position. counterclockwise = positive";
CM_ SG_ 2147491587 DBW_SteeringDriverActivity "Driver is turning the steering wheel, which will switch the DBW system to Manual mode. This flag latches and will unlatch when AKit_SteerCtrlEnblCmd goes back to false.";
CM_ SG_ 2147491587 DBW_SteeringFault "Brake system has a fault, either from the vehicle itself or from an error in the request message from the AKit";
CM_ SG_ 2147491587 DBW_SteeringCtrlType "Indicates whether the DBW kit is set to apply an open loop command (AKit responsible for performing all PID control),
 or requesting the DBW to apply PID control at the actuator level (turn wheel to a certain angle, or apply a certain amount of accel/brake torque & let AKit perform PID control on vehicle curvature/speed)
or requesting the DBW to perform all PID control at the vehicle level (control to a vehicle curvature and speed). If ReqType is 2, the requested speed will be taken from the signal AKit_SpeedReq in the AKit_AccelRequest message.
Some vehicles may not support all types!";
CM_ SG_ 2147491587 DBW_OverheatPreventMode "If the tires are rolling, the steady-state steering torque is relatively low compared to the not-moving case. If the vehicle speed is zero (tires arent rolling) then holding a constant steering angle requires the EPS motor to fight the spring force of the rubber on the pavement. In addition, the EPS system will have to apply this high torque continuously to prevent the steering wheel from springing back to the same angle as the rubber on the pavement. This high-torque for an extended period of time is not something the EPS system would encounter with a human driver because a human would release the steering wheel at 0mph. 

To better replicate the behavior of a human driver in this situation, if the vehicle speed is zero and the AKit steering request has not changed for more than 30 seconds then the DBW will set this flag to indicate that it has zeroed out the steering torque request (though autonomous control may still be enabled). As soon as the AKit steering request changes by a si";
CM_ BO_ 2147491588 "Must be sent continuously, even if you're not planning to enable this actuator.";
CM_ SG_ 2147491588 DBW_BrakePdlDriverInput "Position of actual driver requested brake pedal";
CM_ SG_ 2147491588 DBW_BrakePdlPosnFdbck "Brake pedal command sent to vehicle";
CM_ SG_ 2147491588 DBW_BrakeEnabled "Brake control enabled";
CM_ SG_ 2147491588 DBW_BrakeDriverActivity "Driver is pressing the brakes, which will switch the DBW system to Manual mode. This flag latches and will unlatch when AKit_BrkPdlCtrlEnblCmd goes back to false.";
CM_ SG_ 2147491588 DBW_BrakeFault "Brake system has a fault, either from the vehicle itself or from an error in the request message from the AKit";
CM_ SG_ 2147491588 DBW_BrakeRollingCntr "Watchdog alive rolling counter";
CM_ SG_ 2147491588 DBW_BrakeFault_Ch1 "VCU has detected hardware fault on brake sig 1";
CM_ SG_ 2147491588 DBW_BrakeFault_Ch2 "VCU has detected hardware fault on brake sig 2";
CM_ SG_ 2147491588 DBW_BrakePcntTorqueActual "actual brake torque. This value is in % of a fixed reference value. This reference value depends only on the type of vehicle. Contact New Eagle to determine the reference value for your vehicle make/model.";
CM_ SG_ 2147491588 DBW_BrakeInterventionActv "indicates traction control or ABS on the OEM vehicle is active";
CM_ SG_ 2147491588 DBW_BrakeInterventionReady "indicates traction control or ABS on the OEM vehicle is ready (not disabled but not currently active either)";
CM_ SG_ 2147491588 DBW_BrakeCtrlType "Indicates whether the DBW kit is set to apply an open loop command (AKit responsible for performing all PID control),
 or requesting the DBW to apply PID control at the actuator level (turn wheel to a certain angle, or apply a certain amount of accel/brake torque & let AKit perform PID control on vehicle curvature/speed)
or requesting the DBW to perform all PID control at the vehicle level (control to a vehicle curvature and speed). If ReqType is 2, the requested speed will be taken from the signal AKit_SpeedReq in the AKit_AccelRequest message.
Some vehicles may not support all types!";
CM_ BO_ 2147491589 "Must be sent continuously, even if you're not planning to enable this actuator.";
CM_ SG_ 2147491589 DBW_PrndStateReject "may make this an enum later, after more testing";
CM_ SG_ 2147491589 DBW_PrndDriverActivity "indicates the driver is turning the PRND shift knob";
CM_ SG_ 2147491589 DBW_PrndFault "PRND select system has a fault, either from the vehicle itself or from an error in the request message from the AKit";
CM_ SG_ 2147491589 DBW_PrndCtrlEnabled "PRND select system is under by-wire control. Typically matches the autonomous mode, except in some emergency stop lost-communication scenarios";
CM_ SG_ 2147491590 DBW_WhlPulseCnt_FL "Wheel pulse counter";
CM_ SG_ 2147491590 DBW_WhlPulseCnt_FR "Wheel pulse counter";
CM_ SG_ 2147491590 DBW_WhlPulseCnt_RL "Wheel pulse counter";
CM_ SG_ 2147491590 DBW_WhlPulseCnt_RR "Wheel pulse counter";
CM_ SG_ 2147491590 DBW_WhlPulsesPerRev "Number of wheel pulses in one revolution (96 for the Pacifica)";
CM_ SG_ 2147495682 AKit_AccelPdlReq "Used when AKit_AccelReqType = 0.
For J1939 vehicles with TSC1 control (Volvo), this is a %-of-reference-torque.
For all other vehicles with physical pedal wiring intercepts (Pacifica), this is a %-of-pedal-position";
CM_ SG_ 2147495682 AKit_AccelPdlEnblReq "AKit_GlobalByWireEnblReq must also be true before the DBW system will look at this signal.";
CM_ SG_ 2147495682 AKit_AccelPdlRollingCntr "0-15 rolling counter";
CM_ SG_ 2147495682 AKit_AccelReqType "Indicates whether the AKit is requesting the DBW kit to apply an open loop command (AKit responsible for performing all PID control),
 or requesting the DBW to apply PID control at the actuator level (turn wheel to a certain angle, or apply a certain amount of accel/brake torque & let AKit perform PID control on vehicle curvature/speed)
or requesting the DBW to perform all PID control at the vehicle level (control to a vehicle curvature and speed)
Some vehicles may not support all types! Refer to the **CtrlType feedback from the DBW module to ensure your vehicle supports a given mode";
CM_ SG_ 2147495682 AKit_AccelPcntTorqueReq "Used when AKit_AccelReqType = 1. This mode allows the AKit to request a constant torque value and let the DBW system adjust the pedal position to meet that torque. 

This value is in % of a fixed reference value. This reference value depends only on the type of vehicle. Contact New Eagle to determine the reference value for your vehicle make/model.

Note that the reference value is the same in the braking and AccelPdl control logic. Because any given vehicle's braking system is usually more powerful than it's acceleration system (powertrain), the DBW system will typically reach the max pedal position when only roughly 50% accel torque is requested, again depending on the make/model of the vehicle.";
CM_ SG_ 2147495682 AKit_SpeedReq "Used when AKit_AccelReqType = 2 AND Kit_BrakeCtrllReqType = 2. Both must be 2 because speed control will use both the gas and brake (although a test engineer can leave one of those 2 actuators in manual mode by setting it's ***EnbReq flag to zero, just like in other ***ReqType modes)";
CM_ SG_ 2147495682 AKit_SpeedModeRoadSlope "positive = traveling uphill. Used to adjust the torque requested to meet a given speed (steeper slope requires more torque to hold a constant speed). If this signal is not available, you can send a constant value of zero and speed control will still function but the speed controller will have greater error on sloped surfaces. If internally calibrated to do so, the DBW may also use its own estimate of road slope IFF the AKit is sending exactly 0 for this signal.

The steepest grades in the world are 21 degrees, so this scaling will encompass all real-world roads.

If vehicle is traveling downhill in reverse (facing uphill), this should still be a positive value. the DBW will compensate for PRND direction.";
CM_ SG_ 2147495681 AKit_TurnSignalReq "can't do hazards on pacifica currently";
CM_ SG_ 2147495681 AKit_MiscCmdRollingCntr "0-15 rolling counter";
CM_ SG_ 2147495681 AKit_RightRearDoorReq "Requested state of the given door, if electronically controlled. Currently supported by the Pacifica, but not the Volvo VNR Truck.";
CM_ SG_ 2147495681 AKit_GlobalByWireEnblReq "Global flag to allow by-wire DBW operation. The AKit must send this AND individual actuator enable flags to control any vehicle actuator. Also, if DBW_MiscByWireEnbl goes to zero for any reason uring autonomous driving (driver override, fault, ignition turned off, etc), then this signal must be cycled from 1 to 0 and back to 1 before reenabling autonomous mode. This is in order to acknoledge that the reason for the disable has been addressed and the driver or autonomous system truly wants to return to autonomous operation";
CM_ SG_ 2147495681 AKit_EnblJoystickLimits "For safety & drivability, if this bit is not asserted, the DBW system will assume the vehicle is in joystick demonstration mode. This will limit vehicle speed, relinearize the input requests, rate limit, and clip the various actuators to allow smoother and safer operation while a human is demonstrating DBW operation with a joystick that has a high sensitivity. When a real autonomous system is controlling the DBW (more precise than a human), this bit should be asserted so that the DBW won't apply rate limits, clips, and vehicle speed limits.";
CM_ SG_ 2147495681 AKit_HighBeamReq "Request high beam headlights";
CM_ SG_ 2147495681 AKit_FrontWiperReq "Some vehicles (Volvo) don't support 6 different intermittent speeds. Vovlo only supports 4 intermittent speeds.";
CM_ SG_ 2147495681 AKit_RearWiperReq "Only if a rear wiper is equipped on the vehicle. Some vehicles may not support all speeds shown here.";
CM_ SG_ 2147495681 AKit_IgnitionReq "Not supported on Pacifica, only Volvo";
CM_ SG_ 2147495681 AKit_LeftRearDoorReq "Requested state of the given door, if electronically controlled. Currently supported by the Pacifica, but not the Volvo VNR Truck.";
CM_ SG_ 2147495681 AKit_LiftgateDoorReq "Requested state of the given door, if electronically controlled. Currently supported by the Pacifica, but not the Volvo VNR Truck.";
CM_ SG_ 2147495681 AKit_SoftwareBuildNumber "Build number of the software that is currently running on the AKit system.";
CM_ SG_ 2147495681 AKit_BlockBasicCruiseCtrlBtns "Allows the AKit to tell the DBW to block the driver's buttons presses from passing through the DBW gateway and enabling the vehicle's features. This exists in case the AKit wants to use those inputs for it's own purposes without the vehicle's OEM cruise control system activating";
CM_ SG_ 2147495681 AKit_BlockAdapCruiseCtrlBtns "Allows the AKit to tell the DBW to block the driver's buttons presses from passing through the DBW gateway and enabling the vehicle's features. This exists in case the AKit wants to use those inputs for it's own purposes without the vehicle's OEM cruise control system activating";
CM_ SG_ 2147495681 AKit_BlockTurnSigStalkInpts "Allows the AKit to tell the DBW to block the driver's buttons presses from passing through the DBW gateway and enabling the vehicle's features. This exists in case the AKit wants to use those inputs for it's own purposes without the vehicle's OEM cruise control system activating";
CM_ SG_ 2147495683 AKit_SteeringWhlAngleReq "counterclockwise = positive";
CM_ SG_ 2147495683 AKit_SteeringWhlAngleVelocityLim "0 = infinite rate limit. counterclockwise = positive. Used only when SteeringWhlReqType = 1 or 2.";
CM_ SG_ 2147495683 AKit_SteerCtrlEnblReq "AKit_GlobalByWireEnblReq must also be true before the DBW system will look at this signal.";
CM_ SG_ 2147495683 AKit_SteerRollingCntr "0-15 rolling counter";
CM_ SG_ 2147495683 AKit_SteeringWhlPcntTrqReq "requested steering wheel torque as a percent of a fixed reference value. This reference value depends only on the type of vehicle. Contact New Eagle to determine the reference value for your vehicle make/model.

Used in lieu of AKit_SteeringWhlAnglReq if the AKit is going to handle the PID control to acheive a desired position.";
CM_ SG_ 2147495683 AKit_SteeringReqType "Indicates whether the AKit is requesting the DBW kit to apply an open loop command (AKit responsible for performing all PID control),
 or requesting the DBW to apply PID control at the actuator level (turn wheel to a certain angle, or apply a certain amount of accel/brake torque & let AKit perform PID control on vehicle curvature/speed)
or requesting the DBW to perform all PID control at the vehicle level (control to a vehicle curvature and speed)
Some vehicles may not support all types! Refer to the **CtrlType feedback from the DBW module to ensure your vehicle supports a given mode";
CM_ SG_ 2147495683 AKit_SteeringVehCurvatureReq "Used when AKit_SteeringWhlReqType = 2 (vehicle-level closed loop control). Curvature is the inverse of turn radius, such that 0 curvature = straight. Counterclockwise = positive";
CM_ SG_ 2147495684 AKit_BrakePedalReq "Used when AKit_BrakeCtrlReqType = 0";
CM_ SG_ 2147495684 AKit_BrakeRollingCntr "0-15 rolling counter";
CM_ SG_ 2147495684 AKit_BrakeCtrlEnblReq "AKit_GlobalByWireEnblReq must also be true before the DBW system will look at this signal.";
CM_ SG_ 2147495684 AKit_BrakeCtrlReqType "Indicates whether the AKit is requesting the DBW kit to apply an open loop command (AKit responsible for performing all PID control),
 or requesting the DBW to apply PID control at the actuator level (turn wheel to a certain angle, or apply a certain amount of accel/brake torque & let AKit perform PID control on vehicle curvature/speed)
or requesting the DBW to perform all PID control at the vehicle level (control to a vehicle curvature and speed). If ReqType is 2, the requested speed will be taken from the signal AKit_SpeedReq in the AKit_AccelRequest message.
Some vehicles may not support all types!";
CM_ SG_ 2147495684 AKit_BrakePcntTorqueReq "Used when AKit_BrakeCtrlReqType = 1. This mode allows the AKit to request a constant torque value and let the DBW system adjust the pedal position to meet that torque. 

This value is in % of a fixed reference value. This reference value depends only on the type of vehicle. Contact New Eagle to determine the reference value for your vehicle make/model.";
CM_ SG_ 2147495684 AKit_SpeedModeAccelLim "0 = infinite (no limit). When AKit_AccelReqType = 2 (speed control), the DBW will limit acceleration to this value.
If vehicle is in reverse, this signal will still limit the accelerator pedal value (not the brake)";
CM_ SG_ 2147495684 AKit_SpeedModeDecelLim "0 = infinite (no limit). When AKit_AccelReqType = 2 (speed control), the DBW will limit decceleration to this value.
If vehicle is in reverse, this signal will still limit the brake pedal value (not the accelerator).
Overshoot & settling time requirements cannot be guaranteed with a limit above 7.5m/s^2. the no-limit value, or anything above 7.5m/s^2 should only be used for emergency braking.";
CM_ SG_ 2147495685 AKit_PrndStateReq "PRND shifter position request";
CM_ SG_ 2147495685 AKit_PrndRollingCntr "0-15 rolling counter";
CM_ SG_ 2147495685 AKit_PrndCtrlEnblReq "AKit_GlobalByWireEnblReq must also be true before the DBW system will look at this signal.";
CM_ SG_ 2147491599 DBW_OccupAnyAirbagDeployed "true if there has been a crash";
CM_ SG_ 2147491599 DBW_OccupAnySeatbeltUnbuckled "indicates seatbelt warning lamp is on";
CM_ SG_ 2147491599 DBW_DrvInptCruiseResumeBtn "0 = not pressed, 1 = pressed. Cruise buttons are used to enable autonomous driving if pressed in a special combination";
CM_ SG_ 2147491599 DBW_DrvInptCruiseCancelBtn "0 = not pressed, 1 = pressed. Cruise buttons are used to enable autonomous driving if pressed in a special combination";
CM_ SG_ 2147491599 DBW_DrvInptCruiseAccelBtn "0 = not pressed, 1 = pressed. Cruise buttons are used to enable autonomous driving if pressed in a special combination";
CM_ SG_ 2147491599 DBW_DrvInptCruiseDecelBtn "0 = not pressed, 1 = pressed. Cruise buttons are used to enable autonomous driving if pressed in a special combination";
CM_ SG_ 2147491599 DBW_DrvInptCruiseOnOffBtn "0 = not pressed, 1 = pressed. Cruise buttons are used to enable autonomous driving if pressed in a special combination";
CM_ SG_ 2147491599 DBW_DrvInptAccOnOffBtn "0 = not pressed, 1 = pressed. ACC = adaptive cruise";
CM_ SG_ 2147491599 DBW_DrvInptAccIncDistBtn "0 = not pressed, 1 = pressed. ACC = adaptive cruise";
CM_ SG_ 2147491599 DBW_DrvInptAccDecDistBtn "0 = not pressed, 1 = pressed. ACC = adaptive cruise";
CM_ SG_ 2147491591 DBW_TirePressRR "pacifica TPM_A2 scaling goes from 0 to 126, 1 psi per bit. convert to kpa for standard units here.";
CM_ SG_ 2147491591 DBW_TirePressRL "pacifica TPM_A2 scaling goes from 0 to 126, 1 psi per bit. convert to kpa for standard units here.";
CM_ SG_ 2147491591 DBW_TirePressFR "pacifica TPM_A2 scaling goes from 0 to 126, 1 psi per bit. convert to kpa for standard units here.";
CM_ SG_ 2147491591 DBW_TirePressFL "pacifica TPM_A2 scaling goes from 0 to 126, 1 psi per bit. convert to kpa for standard units here.";
CM_ SG_ 2147491592 DBW_VinMultiplexor "message multiplexor";
CM_ BO_ 2147491593 "Message ID reserved for future addiiton of a GPS sensor.";
CM_ BO_ 2147491594 "IMU = Intertial Measurement Unit";
CM_ SG_ 2147491594 DBW_ImuYawRate "postive = left.";
CM_ SG_ 2147491594 DBW_ImuAccelX "postive = forward.";
CM_ SG_ 2147491594 DBW_ImuAccelY "positive = left.";
CM_ BO_ 2147491595 "Some vehicles send an RPM, others a speed in km/h. Both are multiplexed into this message so that a common DBC can be maintained for New Eagle DBW vehicles";
CM_ SG_ 2147491595 DBW_WhlRpm_RR "positive is forward. Used on Pacifica.";
CM_ SG_ 2147491595 DBW_WhlRpm_RL "positive is forward. Used on Pacifica.";
CM_ SG_ 2147491595 DBW_WhlRpm_FR "positive is forward. Used on Pacifica.";
CM_ SG_ 2147491595 DBW_WhlRpm_FL "positive is forward. Used on Pacifica.";
CM_ SG_ 2147491595 DBW_WhlSpdType "Light duty vehicles (like the Pacifica) broadcast an RPM. J1939 vehicles (like volvo) broadcast a value in road speed (km/h)";
CM_ SG_ 2147491595 DBW_WhlSpd_RR "Positive is forward. Used on Volvo.";
CM_ SG_ 2147491595 DBW_WhlSpd_RL "Positive is forward. Used on Volvo.";
CM_ SG_ 2147491595 DBW_WhlSpd_FR "Positive is forward. Used on Volvo.";
CM_ SG_ 2147491595 DBW_WhlSpd_FL "Positive is forward. Used on Volvo.";
CM_ SG_ 2147491600 DBW_Reserved2 "This signal is reserved for future addition of a gateway module to read the front ACC radar distance from the dedicated radar/camera CAN bus.";
CM_ SG_ 2147491600 DBW_Reserved3 "This signal is reserved for a validity bit for the future addition of a gateway module to read the front ACC radar distance from the dedicated radar/camera CAN bus. This will be false when the Radar module is disabled or faulted.";
CM_ SG_ 2147491600 DBW_SonarVld "indicates if the values from the ultrasonic parking sensors are valid. This will be false when the Park Assist module is disabled or faulted.";
CM_ SG_ 2147491600 DBW_SonarRearDist "distance to nearest rear obstacle";
CM_ BO_ 1807 "ASCII names of faults present in the DBW system";
CM_ SG_ 1807 FltTxt_PageNum "Multiplexor";
CM_ SG_ 1807 FltTxt_FaultId "Index of the fault in Raptor. This number is the output of the Raptor Fault Iterator block. this array can also be accessed by the raptor_get_faults() command in MATLAB.";
CM_ SG_ 1807 FltTxt_NumPages "number of pages in the packet for this one fault, varies depending on how many characters in the fault name";
CM_ SG_ 1807 FltTxt_FaultStatus "status of the fault referenced in the current packet";
CM_ SG_ 1807 FltTxt_FaultSetRuntime "timestamp (during current key cycle) when the fault set";
CM_ SG_ 1807 FltTxt_CRC "custom checksum of the fault packet";
CM_ SG_ 1807 FltTxt_CurrentRuntime "current run time (in the current key cycle)";
CM_ BO_ 2147491601 "Voltage & Current info for the Low Voltage (12V) system";
CM_ SG_ 2147491601 DBW_LvDbwBattVlt "Voltage of the DBW auxiliary battery. Will typically match DBW_LvVehBattVlt, except in a case where the DBW system has opened the LV battery contactor to prevent draining both batteries.";
CM_ SG_ 2147491601 DBW_LvVehBattVlt "Voltage of the Vehicle's main 12V system. Will typically match DBW_LvDbwBattVlt, except in a case where the DBW system has opened the LV battery contactor to prevent draining both batteries.";
CM_ SG_ 2147491601 DBW_LvBattCurr "Current being drawn from the vehicle's OEM 12V battery. This is a measured value on the Pacifica (doesn't include any auxiliary batteries added with the DBW kit). All other vehicles may not support this value or simply report a worst-case estimate based on battery voltage.";
CM_ SG_ 2147491601 DBW_LvDcdcCurr "Current being drawn from the optional DCDC converter supplied by New Eagle. This does not include the current produced by a hybrid vehicle's OEM DCDC converter.";
CM_ SG_ 2147491601 DBW_LvAlternatorCurr "Placeholder. Currently, New Eagle's DBW vehicles do not support this measurement.";
CM_ SG_ 2147491601 DBW_LvBattContactorCmd "True when the DBW system is commanding the relay between the main & auxilliary 12V batteries to close. This will be true when 
1)the vehicle is running (to charge both batteries), or
2) when DBW_LvVehBattVlt is above a safe threshold to source power to the DBW battery, or 
3) when DBW_LvDbwBattVlt is so high that it's clear a charger is connected to the DBW battery such that the DBW system won't draw down the vehicle battery.";
CM_ SG_ 2147491601 DBW_LvInvtrContactorCmd "True when the DBW system is commanding the relay closed between the vehicle's 12V system and the inverter. The inverter draws 200mA when off, so this contactor is just controlled to open when the DBW module is off";
CM_ SG_ 2147491602 DBW_BrakePress_bar "not all vehicles will have the maximum resolution. the scaling and max value are set so that this signal wont need to change between vehicles with hydraulic brakes and vehicles with air brakes.

For example, the Pacifica reports pressure in bar with a range of 0-200bar and resolution of 0.1 bar/bit. The Volvo VNR reports pressure with a range of 0-10bar with a resolution of 0.04 bar/bit";
CM_ SG_ 2147491602 DBW_RoadSlopeEstimate "positive = traveling uphill. Used to adjust the torque requested to meet a given speed (steeper slope requires more torque to hold a constant speed). If a non-zero value is sent over the CAN bus in the message AKit_SpeedModeRoadSlope, the DBW will use that value. If 0 slope is sent from the AKit, the DBW will use zero OR estimate the slope internally (depends on how the internal DBW calibrations are set).

The steepest grades in the world are 21 degrees, so this scaling will encompass all real-world roads.

If vehicle is traveling downhill in reverse (facing uphill), this will still be a positive value.";
CM_ SG_ 2147491603 DBW_SteeringVehCurvatureAct "Curvature is the inverse of turn radius, such that 0 curvature = straight. Counterclockwise = positive";
VAL_ 2147491585 DBW_MiscByWireEnabled 0 "ManualMode" 1 "DriveByWireMode" ;
VAL_ 2147491585 DBW_MiscByWireReady 0 "Not_Ready" 1 "Ready" ;
VAL_ 2147491586 DBW_AccelCtrlType 0 "Open Loop (Pedal %-Positon)" 1 "Actuator-Level Closed Loop (Accelerator %-Torque)" 2 "Vehicle-Level Closed Loop (Vehicle Speed)" ;
VAL_ 2147491587 DBW_SteeringCtrlType 0 "Open Loop (Steering %-Torque)" 1 "Actuator-Level Closed Loop (Steering Wheel Angular Position)" 2 "Vehicle-Level Closed Loop (Vehicle Curvature)" ;
VAL_ 2147491588 DBW_BrakeParkingBrkStatus 0 "Off" 1 "Transitioning" 2 "On" 3 "Fault" ;
VAL_ 2147491588 DBW_BrakeCtrlType 0 "Open Loop (Pedal %-Positon)" 1 "Actuator-Level Closed Loop (Brake %-Torque)" 2 "Vehicle-Level Closed Loop (Vehicle Speed)" ;
VAL_ 2147491589 DBW_PrndStateActual 1 "Park" 2 "Reverse" 3 "Neutral" 4 "Drive" 5 "Low" ;
VAL_ 2147495682 AKit_AccelReqType 0 "Open Loop (Pedal %-Positon)" 1 "Actuator-Level Closed Loop (Accelerator %-Torque)" 2 "Vehicle-Level Closed Loop (Vehicle Speed)" ;
VAL_ 2147495681 AKit_TurnSignalReq 0 "Off" 1 "Left" 2 "Right" ;
VAL_ 2147495681 AKit_RightRearDoorReq 0 "NoRequest" 1 "Close Door" 2 "Open Door" 3 "Undefined" ;
VAL_ 2147495681 AKit_EnblJoystickLimits 0 "Fully Autonomous Control" 1 "Joystick Control Mode" ;
VAL_ 2147495681 AKit_HighBeamReq 0 "No Request" 1 "High Beam If Lights Already On" 2 "Force High Beam On" 3 "Force High Beam Off" ;
VAL_ 2147495681 AKit_FrontWiperReq 0 "Off" 1 "Wiper_Intermittent1" 2 "Wiper_Intermittent2" 3 "Wiper_Intermittent3" 4 "Wiper_Intermittent4" 5 "Wiper_Intermittent5" 6 "Wiper_Intermittent6" 11 "Wiper_ConstantLowSpd" 12 "Wiper_ConstantHighSpd" 13 "Wiper_WashBrief" 14 "Wiper_WashContinuous" ;
VAL_ 2147495681 AKit_RearWiperReq 0 "Off" 1 "Wiper_Intermittent1" 11 "Wiper_ConstantLowSpd" 12 "Wiper_ConstantHighSpd" 13 "Wiper_WashBrief" 14 "Wiper_WashContinuous" ;
VAL_ 2147495681 AKit_IgnitionReq 0 "No Request (Use Key Position)" 1 "Reserved (Force Off Not Currently Supported)" 2 "Reserved (Accessory Command Not Currently Supported)" 3 "Run" 4 "Crank" ;
VAL_ 2147495681 AKit_LeftRearDoorReq 0 "No Request" 1 "Close Door" 2 "Open Door" 3 "Undefined" ;
VAL_ 2147495681 AKit_LiftgateDoorReq 0 "No Request" 1 "Close Door" 2 "Open Door" 3 "Undefined" ;
VAL_ 2147495681 AKit_BlockBasicCruiseCtrlBtns 0 "Pass Through" 1 "Block" ;
VAL_ 2147495681 AKit_BlockAdapCruiseCtrlBtns 0 "Pass Through" 1 "Block" ;
VAL_ 2147495681 AKit_BlockTurnSigStalkInpts 0 "Pass Through" 1 "Block" ;
VAL_ 2147495683 AKit_SteeringReqType 0 "Open Loop (Steering %-Torque)" 1 "Actuator-Level Closed Loop (Steering Wheel Angular Position)" 2 "Vehicle-Level Closed Loop (Vehicle Curvature)" ;
VAL_ 2147495684 AKit_BrakeCtrlReqType 0 "Open Loop (Pedal %-Positon)" 1 "Actuator-Level Closed Loop (Brake %-Torque)" 2 "Vehicle-Level Closed Loop (Vehicle Speed)" ;
VAL_ 2147495685 AKit_PrndStateReq 1 "Park" 2 "Reverse" 3 "Neutral" 4 "Drive" 5 "Low" 0 "No Request" ;
VAL_ 2147491599 DBW_DrvInptHiBeam 0 "Off" 1 "On" 2 "Flash" ;
VAL_ 2147491599 DBW_DrvInptTurnSignal 0 "Off" 1 "Left" 2 "Right" ;
VAL_ 2147491599 DBW_DrvInptWiper 0 "Off" 1 "Wiper_Intermittent1" 2 "Wiper_Intermittent2" 3 "Wiper_Intermittent3" 4 "Wiper_Intermittent4" 5 "Wiper_Intermittent5" 6 "Wiper_Intermittent6" 11 "Wiper_ConstantLowSpd" 12 "Wiper_ConstantHighSpd" 13 "Wiper_WashBrief" 14 "Wiper_WashContinuous" ;
VAL_ 2147491595 DBW_WhlSpdType 0 "RPM" 1 "km/h (Front)" 2 "km/h (Rear)" ;
VAL_ 2147491600 DBW_SonarArcNumRR 15 "No ARC" 8 "ARC8" 7 "ARC7" 6 "ARC6" 5 "ARC5" 4 "ARC4" 3 "ARC3" 2 "ARC2" 1 "ARC1" 0 "NODist" ;
VAL_ 2147491600 DBW_SonarArcNumRL 15 "No ARC" 8 "ARC8" 7 "ARC7" 6 "ARC6" 5 "ARC5" 4 "ARC4" 3 "ARC3" 2 "ARC2" 1 "ARC1" 0 "NODist" ;
VAL_ 2147491600 DBW_SonarArcNumRC 15 "No ARC" 8 "ARC8" 7 "ARC7" 6 "ARC6" 5 "ARC5" 4 "ARC4" 3 "ARC3" 2 "ARC2" 1 "ARC1" 0 "NODist" ;
VAL_ 2147491600 DBW_SonarArcNumFR 15 "No ARC" 8 "ARC8" 7 "ARC7" 6 "ARC6" 5 "ARC5" 4 "ARC4" 3 "ARC3" 2 "ARC2" 1 "ARC1" 0 "NODist" ;
VAL_ 2147491600 DBW_SonarArcNumFL 15 "No ARC" 8 "ARC8" 7 "ARC7" 6 "ARC6" 5 "ARC5" 4 "ARC4" 3 "ARC3" 2 "ARC2" 1 "ARC1" 0 "NODist" ;
VAL_ 2147491600 DBW_SonarArcNumFC 15 "No ARC" 8 "ARC8" 7 "ARC7" 6 "ARC6" 5 "ARC5" 4 "ARC4" 3 "ARC3" 2 "ARC2" 1 "ARC1" 0 "NODist" ;
VAL_ 1807 FltTxt_FaultStatus 1 "Occurred" 2 "Active" ;
